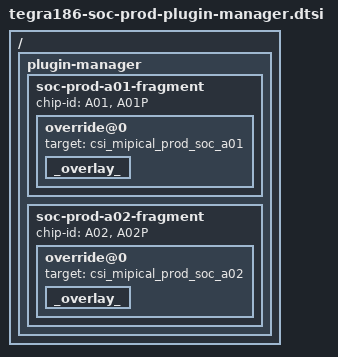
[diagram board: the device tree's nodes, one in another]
/*
 * tegra186-soc-prod-plugin-manager.dtsi: Run time override for the soc
 *	specific prod setting.
 *
 * Copyright (c) 2015-2016, NVIDIA CORPORATION.  All rights reserved.
 *
 * This program is free software; you can redistribute it and/or modify
 * it under the terms of the GNU General Public License as published by
 * the Free Software Foundation; version 2 of the License.
 */

/ {
	plugin-manager {
		soc-prod-a01-fragment {
			chip-id = "A01", "A01P";
			override@0 {
				target = <&csi_mipical_prod_soc_a01>;
				_overlay_ {
					status = "okay";
				};
			};
		};

		soc-prod-a02-fragment {
			chip-id = "A02", "A02P";
			override@0 {
				target = <&csi_mipical_prod_soc_a02>;
				_overlay_ {
					status = "okay";
				};
			};
		};
	};
};
